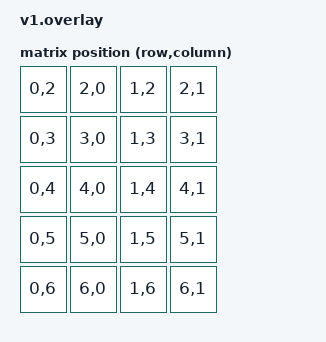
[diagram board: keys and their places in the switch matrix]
// This file was generated from a template. Edit it to match your keyboard.
// See https://zmk.dev/docs/development/hardware-integration/new-shield for more
// instructions.

#include <dt-bindings/zmk/matrix_transform.h>


/ {
    chosen {
        zmk,kscan = &kscan0;
        zmk,matrix-transform = &default_transform;
    };

    kscan0: kscan_0 {
        compatible = "zmk,kscan-gpio-charlieplex";
        label = "KSCAN";
        wakeup-source;

        // Replace these comments with the GPIO pins in the matrix.
        // See https://zmk.dev/docs/development/hardware-integration/new-shield#shield-overlays
        gpios
            = <&pro_micro 19 GPIO_ACTIVE_HIGH>
            , <&pro_micro 20 GPIO_ACTIVE_HIGH>
            , <&pro_micro 3 GPIO_ACTIVE_HIGH>
            , <&pro_micro 4 GPIO_ACTIVE_HIGH>
            , <&pro_micro 5 GPIO_ACTIVE_HIGH>
            , <&pro_micro 6 GPIO_ACTIVE_HIGH>
            , <&pro_micro 7 GPIO_ACTIVE_HIGH>
            ;

        //interrupt-gpios = <&pro_micro 002 (GPIO_ACTIVE_HIGH | GPIO_PULL_DOWN)>;
    };

    default_transform: default_transform {
        // See https://zmk.dev/docs/development/hardware-integration/new-shield#matrix-transform
        // for how to configure this
        compatible = "zmk,matrix-transform";
        columns = <4>;
        rows = <5>;

        map = <
            RC(0, 2) RC(2, 0) RC(1, 2) RC(2, 1)
            RC(0, 3) RC(3, 0) RC(1, 3) RC(3, 1)
            RC(0, 4) RC(4, 0) RC(1, 4) RC(4, 1)
            RC(0, 5) RC(5, 0) RC(1, 5) RC(5, 1)
            RC(0, 6) RC(6, 0) RC(1, 6) RC(6, 1)
        >;
    };
};

// Disable I2C (Unlocks Pin 3)
&i2c0 { status = "disabled"; };

// Disable SPI (Unlocks Pins 4, 5, 6)
&spi0 { status = "disabled"; };
&spi1 { status = "disabled"; };
&spi2 { status = "disabled"; };


